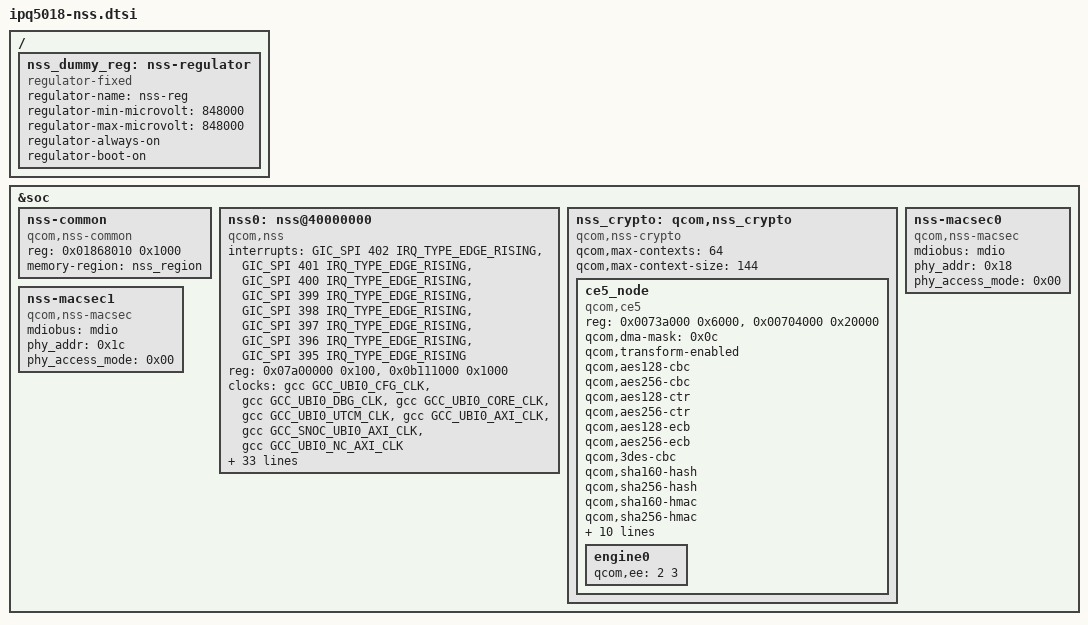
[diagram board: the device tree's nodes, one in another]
// SPDX-License-Identifier: GPL-2.0-or-later OR MIT

/ {
	nss_dummy_reg: nss-regulator {
		compatible = "regulator-fixed";
		regulator-name = "nss-reg";
		regulator-min-microvolt = <848000>;
		regulator-max-microvolt = <848000>;
		regulator-always-on;
		regulator-boot-on;
	};
};

&soc {
	nss-common {
		compatible = "qcom,nss-common";
		reg = <0x01868010 0x1000>;
		reg-names = "nss-misc-reset";
		memory-region = <&nss_region>;
	};

	nss0: nss@40000000 {
		compatible = "qcom,nss";
		interrupts = <GIC_SPI 402 IRQ_TYPE_EDGE_RISING>,
					<GIC_SPI 401 IRQ_TYPE_EDGE_RISING>,
					<GIC_SPI 400 IRQ_TYPE_EDGE_RISING>,
					<GIC_SPI 399 IRQ_TYPE_EDGE_RISING>,
					<GIC_SPI 398 IRQ_TYPE_EDGE_RISING>,
					<GIC_SPI 397 IRQ_TYPE_EDGE_RISING>,
					<GIC_SPI 396 IRQ_TYPE_EDGE_RISING>,
					<GIC_SPI 395 IRQ_TYPE_EDGE_RISING>;
		reg = <0x07a00000 0x100>, <0x0b111000 0x1000>;
		reg-names = "nphys", "qgic-phys";
		clocks = <&gcc GCC_UBI0_CFG_CLK>,
				<&gcc GCC_UBI0_DBG_CLK>,
				<&gcc GCC_UBI0_CORE_CLK>,
				<&gcc GCC_UBI0_UTCM_CLK>,
				<&gcc GCC_UBI0_AXI_CLK>,
				<&gcc GCC_SNOC_UBI0_AXI_CLK>,
				<&gcc GCC_UBI0_NC_AXI_CLK>;
		clock-names = "nss-cfg-clk",
					"nss-dbg-clk",
					"nss-core-clk",
					"nss-utcm-clk",
					"nss-axi-clk",
					"nss-snoc-axi-clk",
					"nss-nc-axi-clk";
		qcom,id = <0>;
		qcom,num-queue = <4>;
		qcom,num-irq = <8>;
		qcom,num-pri = <4>;
		qcom,load-addr = <0x40000000>;
		qcom,low-frequency = <850000000>;
		qcom,mid-frequency = <850000000>;
		qcom,max-frequency = <1000000000>;
		qcom,ipv4-enabled;
		qcom,ipv4-reasm-enabled;
		qcom,ipv6-enabled;
		qcom,ipv6-reasm-enabled;
		qcom,tun6rd-enabled;
		qcom,l2tpv2-enabled;
		qcom,gre-enabled;
		qcom,map-t-enabled;
		qcom,pppoe-enabled;
		qcom,pptp-enabled;
		qcom,tunipip6-enabled;
		qcom,shaping-enabled;
		qcom,clmap-enabled;
		qcom,vxlan-enabled;
		qcom,match-enabled;
		qcom,mirror-enabled;
		qcom,crypto-enabled;
		qcom,ipsec-enabled;
		qcom,wlanredirect-enabled;
		qcom,gre-redir-enabled;
		qcom,gre-redir-mark-enabled;
		qcom,portid-enabled;
		qcom,wlan-dataplane-offload-enabled;
		qcom,pvxlan-enabled;
		qcom,udp-st-enabled;
	};

	nss_crypto: qcom,nss_crypto {
		compatible = "qcom,nss-crypto";
		#address-cells = <1>;
		#size-cells = <1>;
		qcom,max-contexts = <64>;
		qcom,max-context-size = <144>;
		ranges;
		ce5_node {
			compatible = "qcom,ce5";
			reg-names = "crypto_pbase", "bam_base";
			reg = <0x0073a000 0x6000>, <0x00704000 0x20000>;
			qcom,dma-mask = <0x0c>;
			qcom,transform-enabled;
			qcom,aes128-cbc;
			qcom,aes256-cbc;
			qcom,aes128-ctr;
			qcom,aes256-ctr;
			qcom,aes128-ecb;
			qcom,aes256-ecb;
			qcom,3des-cbc;
			qcom,sha160-hash;
			qcom,sha256-hash;
			qcom,sha160-hmac;
			qcom,sha256-hmac;
			qcom,aes128-cbc-sha160-hmac;
			qcom,aes256-cbc-sha160-hmac;
			qcom,aes128-ctr-sha160-hmac;
			qcom,aes256-ctr-sha160-hmac;
			qcom,3des-cbc-sha160-hmac;
			qcom,3des-cbc-sha256-hmac;
			qcom,aes128-cbc-sha256-hmac;
			qcom,aes256-cbc-sha256-hmac;
			qcom,aes128-ctr-sha256-hmac;
			qcom,aes256-ctr-sha256-hmac;
			engine0 {
				qcom,ee = <2 3>;
			};
		};
	};

	nss-macsec0 {
		compatible = "qcom,nss-macsec";
		mdiobus = <&mdio>;
		phy_addr = <0x18>;
		phy_access_mode = <0x00>;
	};

	nss-macsec1 {
		compatible = "qcom,nss-macsec";
		mdiobus = <&mdio>;
		phy_addr = <0x1c>;
		phy_access_mode = <0x00>;
	};

};
